# CY8C3866AXI_040 register map
File version: 0.1
CY8C38
Registers are 8-bit, read-write, no defined reset value unless marked. A register's access mark holds for its fields unless they carry their own. Offsets are from the block's base; lines under a group give offsets from that group; [hi:lo] are bit positions; {n}, {i} and the like mark numbered series; 'fields as' and 'values as' point back to an identical list; <NAME> marks a mode.

## Memory map
0x00000000 SEC_TIL_BLACK_TIMER
0x00000000 MOTOR_PWM
0x00000000 LINE_COUNTER
0x00000000 STEERING_PWM
0x00000000 HE_TIMER
0x00006575 DIR_REG

## SEC_TIL_BLACK_TIMER
Base 0x00000000
0x6404 SEC_TIL_BLACK_TIMER_COUNTER 32-bit — UDB.A0 - Current Down Counter Value
0x6424 SEC_TIL_BLACK_TIMER_PERIOD 32-bit — UDB.D0 - Assigned Period
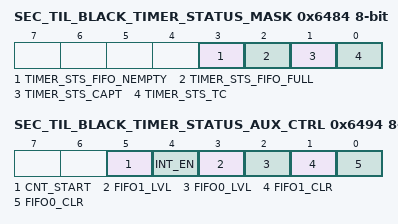
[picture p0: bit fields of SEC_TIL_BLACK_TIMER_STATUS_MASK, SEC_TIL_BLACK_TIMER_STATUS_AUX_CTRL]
0x6484 SEC_TIL_BLACK_TIMER_STATUS_MASK — UDB Status bits Interrupt Mask Enable Register
  [3] TIMER_STS_FIFO_NEMPTY ro — FIFO Empty status
  [2] TIMER_STS_FIFO_FULL ro — FIFO Full Status
  [1] TIMER_STS_CAPT ro — Enables the Interrupt on Capture
  [0] TIMER_STS_TC ro — Enables the Interrupt on TC
0x6494 SEC_TIL_BLACK_TIMER_STATUS_AUX_CTRL — UDB Auxilliary Control Register
  [5] CNT_START — FIFO0 clear
    0=E_CNT_START0 (Disable counter); 1=E_CNT_START1 (Enable counter)
  [4] INT_EN
    0=E_INT_EN0 (Interrupt disabled); 1=E_INT_EN1 (Interrupt enabled)
  [3] FIFO1_LVL — FIFO level
    0=E_FIFO_LVL_0 (FIFO LVL: input mode: FIFO not full; output mode: FIFO not empty); 1=E_FIFO_LVL_1 (FIFO LVL: input mode: FIFO at least 1/2 empty; output mode: FIFO at least 1/2 full)
  [2] FIFO0_LVL — FIFO level
    values as FIFO1_LVL
  [1] FIFO1_CLR — FIFO1 clear
    0=E_FIFO_CLR_0 (Normal FIFO operation); 1=E_FIFO_CLR_1 (Clear FIFO state)
  [0] FIFO0_CLR — FIFO0 clear
    values as FIFO1_CLR

## DIR_REG
Base 0x00006575
0x00 DIR_REG_CONTROL_REG

## MOTOR_PWM
Base 0x00000000
0x652A MOTOR_PWM_COMPARE_Reg 16-bit — UDB.D0 - Assigned Compare Value
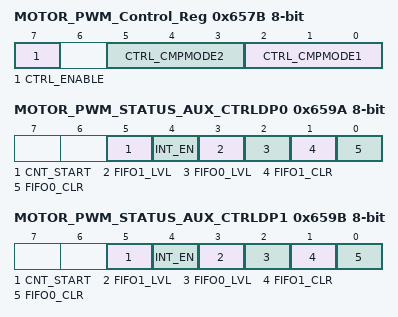
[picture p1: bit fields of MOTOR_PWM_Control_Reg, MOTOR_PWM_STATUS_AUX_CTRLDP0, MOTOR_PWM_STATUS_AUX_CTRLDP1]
0x657B MOTOR_PWM_Control_Reg — UDB Control Register - Assigned Control Register Value
  [7] CTRL_ENABLE — Enable the PWM
  [5:3] CTRL_CMPMODE2 — Compare mode 2
  [2:0] CTRL_CMPMODE1 — Compare mode 1
0x659A MOTOR_PWM_STATUS_AUX_CTRLDP0 — UDB Auxilliary Control Register
  fields as SEC_TIL_BLACK_TIMER.SEC_TIL_BLACK_TIMER_STATUS_AUX_CTRL
0x659B MOTOR_PWM_STATUS_AUX_CTRLDP1 — UDB Auxilliary Control Register
  fields as SEC_TIL_BLACK_TIMER.SEC_TIL_BLACK_TIMER_STATUS_AUX_CTRL

## LINE_COUNTER
Base 0x00000000
0x6400 LINE_COUNTER_COUNTER 32-bit — UDB.A0 - Current Counter Value
0x6420 LINE_COUNTER_PERIOD 32-bit — UDB.D0 - Assigned Period
0x6430 LINE_COUNTER_COMPARE 32-bit — UDB.D1 - Assigned Compare Value
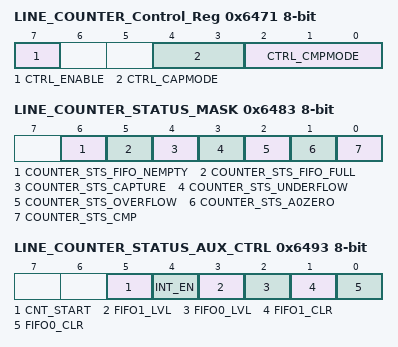
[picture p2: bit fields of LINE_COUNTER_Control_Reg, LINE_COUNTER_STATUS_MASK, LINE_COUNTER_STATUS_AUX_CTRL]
0x6471 LINE_COUNTER_Control_Reg — UDB Control Register - Assigned Control Register Value
  [7] CTRL_ENABLE — Enable Counter
  [4:3] CTRL_CAPMODE — Capture mode
  [2:0] CTRL_CMPMODE — Compare mode
0x6483 LINE_COUNTER_STATUS_MASK — UDB Status bits Interrupt Mask Enable Register
  [6] COUNTER_STS_FIFO_NEMPTY — FIFO Not Empty Status
  [5] COUNTER_STS_FIFO_FULL — FIFO Full Status
  [4] COUNTER_STS_CAPTURE — Capture Status
  [3] COUNTER_STS_UNDERFLOW — Underflow status
  [2] COUNTER_STS_OVERFLOW — Overflow status
  [1] COUNTER_STS_A0ZERO — A0 Zero ouput status
  [0] COUNTER_STS_CMP — Compare output status
0x6493 LINE_COUNTER_STATUS_AUX_CTRL — UDB Auxilliary Control Register
  fields as SEC_TIL_BLACK_TIMER.SEC_TIL_BLACK_TIMER_STATUS_AUX_CTRL

## STEERING_PWM
Base 0x00000000
0x642C STEERING_PWM_COMPARE_Reg 16-bit — UDB.D0 - Assigned Compare Value
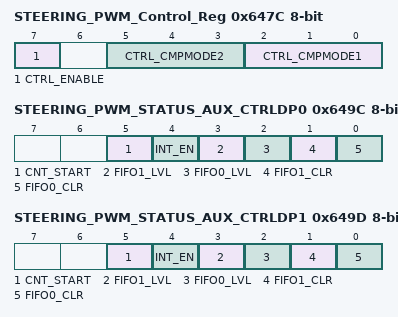
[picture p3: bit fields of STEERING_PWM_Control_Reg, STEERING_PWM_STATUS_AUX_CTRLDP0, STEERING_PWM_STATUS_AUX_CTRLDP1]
0x647C STEERING_PWM_Control_Reg — UDB Control Register - Assigned Control Register Value
  [7] CTRL_ENABLE — Enable the PWM
  [5:3] CTRL_CMPMODE2 — Compare mode 2
  [2:0] CTRL_CMPMODE1 — Compare mode 1
0x649C STEERING_PWM_STATUS_AUX_CTRLDP0 — UDB Auxilliary Control Register
  fields as SEC_TIL_BLACK_TIMER.SEC_TIL_BLACK_TIMER_STATUS_AUX_CTRL
0x649D STEERING_PWM_STATUS_AUX_CTRLDP1 — UDB Auxilliary Control Register
  fields as SEC_TIL_BLACK_TIMER.SEC_TIL_BLACK_TIMER_STATUS_AUX_CTRL

## HE_TIMER
Base 0x00000000
0x6504 HE_TIMER_COUNTER 32-bit — UDB.A0 - Current Down Counter Value
0x6524 HE_TIMER_PERIOD 32-bit — UDB.D0 - Assigned Period
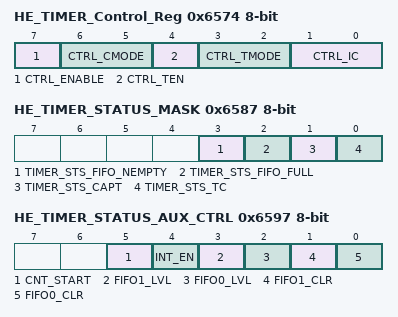
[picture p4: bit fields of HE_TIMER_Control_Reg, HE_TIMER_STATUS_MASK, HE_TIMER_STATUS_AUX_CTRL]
0x6574 HE_TIMER_Control_Reg — UDB Control Register - Assigned Control Register Value
  [7] CTRL_ENABLE — Enable the Timer
  [6:5] CTRL_CMODE — Capture Mode
  [4] CTRL_TEN — Trigger Enable Bit
  [3:2] CTRL_TMODE — Trigger Mode
  [1:0] CTRL_IC — Interrupt Count
0x6587 HE_TIMER_STATUS_MASK — UDB Status bits Interrupt Mask Enable Register
  fields as SEC_TIL_BLACK_TIMER.SEC_TIL_BLACK_TIMER_STATUS_MASK
0x6597 HE_TIMER_STATUS_AUX_CTRL — UDB Auxilliary Control Register
  fields as SEC_TIL_BLACK_TIMER.SEC_TIL_BLACK_TIMER_STATUS_AUX_CTRL
